VERSION ""

NS_ :

BS_:

BU_: GW Steering Brake
VAL_TABLE_ VT_CCAN_Boolean 1 "TRUE" 0 "FALSE" ;

BO_ 256 MSG_SteeringWheelInfo: 3 Steering
 SG_ SIG_SteeringWheelAngle : 8|11@1- (1,0) [-540|540] "degree"  GW
 SG_ SIG_Crc : 0|8@1+ (1,0) [0|255] ""  GW

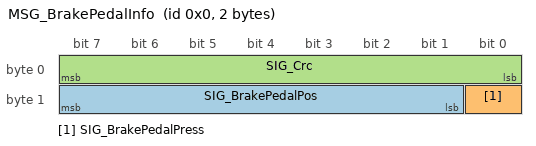
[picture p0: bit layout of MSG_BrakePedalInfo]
BO_ 0 MSG_BrakePedalInfo: 2 Brake
 SG_ SIG_BrakePedalPos : 9|7@1+ (1,0) [0|100] "%"  GW
 SG_ SIG_BrakePedalPress : 8|1@1+ (1,0) [0|1] ""  GW
 SG_ SIG_Crc : 0|8@1+ (1,0) [0|255] ""  GW

VAL_ 0 SIG_BrakePedalPress 1 "TRUE" 0 "FALSE" ;
